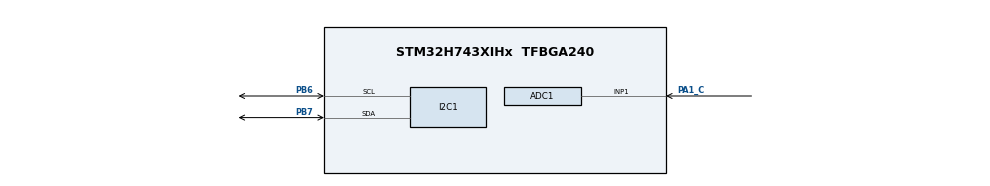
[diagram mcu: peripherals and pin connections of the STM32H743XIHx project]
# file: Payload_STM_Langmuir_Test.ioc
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ADC1.Channel-1\#ChannelRegularConversion=ADC_CHANNEL_1
ADC1.NbrOfConversionFlag=1
ADC1.OffsetNumber-1\#ChannelRegularConversion=ADC_OFFSET_NONE
ADC1.OffsetSignedSaturation-1\#ChannelRegularConversion=DISABLE
ADC1.Rank-1\#ChannelRegularConversion=1
ADC1.SamplingTime-1\#ChannelRegularConversion=ADC_SAMPLETIME_1CYCLE_5
ADC1.master=1
CORTEX_M7.default_mode_Activation=1
I2C1.Timing=0x00707CBB
Mcu.Family=STM32H7
Mcu.Name=STM32H743XIHx
Mcu.Package=TFBGA240
NVIC.PriorityGroup=NVIC_PRIORITYGROUP_4
PA1_C.Signal=ADCx_INP1
PB6.Mode=I2C
PB6.Signal=I2C1_SCL
PB7.Mode=I2C
PB7.Signal=I2C1_SDA
ProjectManager.HeapSize=0x200
ProjectManager.StackSize=0x400
ProjectManager.TargetToolchain=STM32CubeIDE
RCC.ADCFreq_Value=75000000
RCC.APB1Freq_Value=32000000
RCC.APB2Freq_Value=64000000
RCC.APB3Freq_Value=64000000
RCC.APB4Freq_Value=64000000
RCC.CortexFreq_Value=64000000
RCC.D2PPRE1=RCC_APB1_DIV2
RCC.DIVM2=4
RCC.DIVN2=9
RCC.HCLKFreq_Value=64000000
RCC.PLL2FRACN=3072
RCC.SYSCLKFreq_VALUE=64000000
RCC.USBFreq_Value=129000000
SH.ADCx_INP1.0=ADC1_INP1,IN1-Single-Ended
VP_MEMORYMAP_VS_MEMORYMAP.Mode=CurAppReg
board=custom

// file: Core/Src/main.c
/* USER CODE BEGIN Header */
/**
  ******************************************************************************
  * @file           : main.c
  * @brief          : Main program body
  ******************************************************************************
  * @attention
  *
  * Copyright (c) 2026 STMicroelectronics.
  * All rights reserved.
  *
  * This software is licensed under terms that can be found in the LICENSE file
  * in the root directory of this software component.
  * If no LICENSE file comes with this software, it is provided AS-IS.
  *
  ******************************************************************************
  */
/* USER CODE END Header */
#include "main.h"

#define MCP3021_ADDR  (0x4D << 1)  // 7-bit addr shifted for HAL
#define MEAS_BUFFER_SIZE 100 // Keep this many values

/**
 * Reads the raw 10-bit ADC value from MCP3021.
 * Returns -1 on I2C error.
 */
int32_t MCP3021_ReadRaw(I2C_HandleTypeDef *hi2c)
{
    uint8_t buf[2] = {0};

    if (HAL_I2C_Master_Receive(hi2c, MCP3021_ADDR, buf, 2, HAL_MAX_DELAY) != HAL_OK)
        return -1;

    // Data is 10-bit, MSB first, left-justified across two bytes
    // Bits [15:6] of the 16-bit word are the ADC data
    uint16_t raw = ((uint16_t)buf[0] << 8) | buf[1];
    raw = (raw >> 2) & 0x03FF;  // shift right 2, mask to 10 bits (SAR format)

    return (int32_t)raw;
}

/**
 * Converts raw ADC value to voltage (assuming 3.3V reference).
 */
float MCP3021_ReadVoltage(I2C_HandleTypeDef *hi2c)
{
    int32_t raw = MCP3021_ReadRaw(hi2c);
    if (raw < 0) return -1.0f;

    return ((float)raw / 1023.0f) * 3.3f;
}

ADC_HandleTypeDef hadc1;

I2C_HandleTypeDef hi2c1;

void SystemClock_Config(void);
static void MPU_Config(void);
static void MX_GPIO_Init(void);
static void MX_I2C1_Init(void);
static void MX_ADC1_Init(void);

int main(void)
{

  /* MPU Configuration--------------------------------------------------------*/
  MPU_Config();

  /* MCU Configuration--------------------------------------------------------*/

  /* Reset of all peripherals, Initializes the Flash interface and the Systick. */
  HAL_Init();

  /* Configure the system clock */
  SystemClock_Config();

  /* Initialize all configured peripherals */
  MX_GPIO_Init();
  MX_I2C1_Init();
  MX_ADC1_Init();
  /* USER CODE BEGIN 2 */

  HAL_ADCEx_Calibration_Start(&hadc1, ADC_CALIB_OFFSET, ADC_SINGLE_ENDED);

  /* USER CODE END 2 */

  /* Infinite loop */
  while (1)
  {

	    uint8_t buf[2] = {0};
	    i2c_status = HAL_I2C_Master_Receive(&hi2c1, MCP3021_ADDR, buf, 2, HAL_MAX_DELAY);
	    i2c_error  = HAL_I2C_GetError(&hi2c1);

	    // Read raw voltages
	    voltage_triangle = MCP3021_ReadVoltage(&hi2c1);
	    voltage_langmuir = ReadInternalADC(); // Read voltages

	    // Calculate voltage and current
	    voltage = (voltage_triangle * 169.0f) - 266.4f;
	    current = (((voltage_langmuir * 70.3f) - 109.9f) - voltage) / 3000.0f; // Calculate current and voltage

	    // Add to memory
	    measurements_voltage[meas_index] = voltage;
	    measurements_current[meas_index] = current;
	    meas_index = (meas_index + 1) % MEAS_BUFFER_SIZE;

	    HAL_Delay(100);  // Read every 100ms

  }
}

void SystemClock_Config(void)
{
  RCC_OscInitTypeDef RCC_OscInitStruct = {0};
  RCC_ClkInitTypeDef RCC_ClkInitStruct = {0};

  /** Supply configuration update enable
  */
  HAL_PWREx_ConfigSupply(PWR_LDO_SUPPLY);

  /** Configure the main internal regulator output voltage
  */
  __HAL_PWR_VOLTAGESCALING_CONFIG(PWR_REGULATOR_VOLTAGE_SCALE3);

  while(!__HAL_PWR_GET_FLAG(PWR_FLAG_VOSRDY)) {}

  /** Macro to configure the PLL clock source
  */
  __HAL_RCC_PLL_PLLSOURCE_CONFIG(RCC_PLLSOURCE_HSI);

  /** Initializes the RCC Oscillators according to the specified parameters
  * in the RCC_OscInitTypeDef structure.
  */
  RCC_OscInitStruct.OscillatorType = RCC_OSCILLATORTYPE_HSI;
  RCC_OscInitStruct.HSIState = RCC_HSI_DIV1;
  RCC_OscInitStruct.HSICalibrationValue = RCC_HSICALIBRATION_DEFAULT;
  RCC_OscInitStruct.PLL.PLLState = RCC_PLL_NONE;
  if (HAL_RCC_OscConfig(&RCC_OscInitStruct) != HAL_OK)
  {
    Error_Handler();
  }

  /** Initializes the CPU, AHB and APB buses clocks
  */
  RCC_ClkInitStruct.ClockType = RCC_CLOCKTYPE_HCLK|RCC_CLOCKTYPE_SYSCLK
                              |RCC_CLOCKTYPE_PCLK1|RCC_CLOCKTYPE_PCLK2
                              |RCC_CLOCKTYPE_D3PCLK1|RCC_CLOCKTYPE_D1PCLK1;
  RCC_ClkInitStruct.SYSCLKSource = RCC_SYSCLKSOURCE_HSI;
  RCC_ClkInitStruct.SYSCLKDivider = RCC_SYSCLK_DIV1;
  RCC_ClkInitStruct.AHBCLKDivider = RCC_HCLK_DIV1;
  RCC_ClkInitStruct.APB3CLKDivider = RCC_APB3_DIV1;
  RCC_ClkInitStruct.APB1CLKDivider = RCC_APB1_DIV2;
  RCC_ClkInitStruct.APB2CLKDivider = RCC_APB2_DIV1;
  RCC_ClkInitStruct.APB4CLKDivider = RCC_APB4_DIV1;

  if (HAL_RCC_ClockConfig(&RCC_ClkInitStruct, FLASH_LATENCY_1) != HAL_OK)
  {
    Error_Handler();
  }
}

static void MX_ADC1_Init(void)
{

  ADC_MultiModeTypeDef multimode = {0};
  ADC_ChannelConfTypeDef sConfig = {0};

  /** Common config
  */
  hadc1.Instance = ADC1;
  hadc1.Init.ClockPrescaler = ADC_CLOCK_ASYNC_DIV2;
  hadc1.Init.Resolution = ADC_RESOLUTION_16B;
  hadc1.Init.ScanConvMode = ADC_SCAN_DISABLE;
  hadc1.Init.EOCSelection = ADC_EOC_SINGLE_CONV;
  hadc1.Init.LowPowerAutoWait = DISABLE;
  hadc1.Init.ContinuousConvMode = DISABLE;
  hadc1.Init.NbrOfConversion = 1;
  hadc1.Init.DiscontinuousConvMode = DISABLE;
  hadc1.Init.ExternalTrigConv = ADC_SOFTWARE_START;
  hadc1.Init.ExternalTrigConvEdge = ADC_EXTERNALTRIGCONVEDGE_NONE;
  hadc1.Init.ConversionDataManagement = ADC_CONVERSIONDATA_DR;
  hadc1.Init.Overrun = ADC_OVR_DATA_PRESERVED;
  hadc1.Init.LeftBitShift = ADC_LEFTBITSHIFT_NONE;
  hadc1.Init.OversamplingMode = DISABLE;
  hadc1.Init.Oversampling.Ratio = 1;
  if (HAL_ADC_Init(&hadc1) != HAL_OK)
  {
    Error_Handler();
  }

  /** Configure the ADC multi-mode
  */
  multimode.Mode = ADC_MODE_INDEPENDENT;
  if (HAL_ADCEx_MultiModeConfigChannel(&hadc1, &multimode) != HAL_OK)
  {
    Error_Handler();
  }

  /** Configure Regular Channel
  */
  sConfig.Channel = ADC_CHANNEL_1;
  sConfig.Rank = ADC_REGULAR_RANK_1;
  sConfig.SamplingTime = ADC_SAMPLETIME_1CYCLE_5;
  sConfig.SingleDiff = ADC_SINGLE_ENDED;
  sConfig.OffsetNumber = ADC_OFFSET_NONE;
  sConfig.Offset = 0;
  sConfig.OffsetSignedSaturation = DISABLE;
  if (HAL_ADC_ConfigChannel(&hadc1, &sConfig) != HAL_OK)
  {
    Error_Handler();
  }

}

static void MX_I2C1_Init(void)
{

  hi2c1.Instance = I2C1;
  hi2c1.Init.Timing = 0x00707CBB;
  hi2c1.Init.OwnAddress1 = 0;
  hi2c1.Init.AddressingMode = I2C_ADDRESSINGMODE_7BIT;
  hi2c1.Init.DualAddressMode = I2C_DUALADDRESS_DISABLE;
  hi2c1.Init.OwnAddress2 = 0;
  hi2c1.Init.OwnAddress2Masks = I2C_OA2_NOMASK;
  hi2c1.Init.GeneralCallMode = I2C_GENERALCALL_DISABLE;
  hi2c1.Init.NoStretchMode = I2C_NOSTRETCH_DISABLE;
  if (HAL_I2C_Init(&hi2c1) != HAL_OK)
  {
    Error_Handler();
  }

  /** Configure Analogue filter
  */
  if (HAL_I2CEx_ConfigAnalogFilter(&hi2c1, I2C_ANALOGFILTER_ENABLE) != HAL_OK)
  {
    Error_Handler();
  }

  /** Configure Digital filter
  */
  if (HAL_I2CEx_ConfigDigitalFilter(&hi2c1, 0) != HAL_OK)
  {
    Error_Handler();
  }

}

static void MX_GPIO_Init(void)
{

  /* GPIO Ports Clock Enable */
  __HAL_RCC_GPIOB_CLK_ENABLE();
  __HAL_RCC_GPIOA_CLK_ENABLE();

}

 /* MPU Configuration */

void MPU_Config(void)
{
  MPU_Region_InitTypeDef MPU_InitStruct = {0};

  /* Disables the MPU */
  HAL_MPU_Disable();

  /** Initializes and configures the Region and the memory to be protected
  */
  MPU_InitStruct.Enable = MPU_REGION_ENABLE;
  MPU_InitStruct.Number = MPU_REGION_NUMBER0;
  MPU_InitStruct.BaseAddress = 0x0;
  MPU_InitStruct.Size = MPU_REGION_SIZE_4GB;
  MPU_InitStruct.SubRegionDisable = 0x87;
  MPU_InitStruct.TypeExtField = MPU_TEX_LEVEL0;
  MPU_InitStruct.AccessPermission = MPU_REGION_NO_ACCESS;
  MPU_InitStruct.DisableExec = MPU_INSTRUCTION_ACCESS_DISABLE;
  MPU_InitStruct.IsShareable = MPU_ACCESS_SHAREABLE;
  MPU_InitStruct.IsCacheable = MPU_ACCESS_NOT_CACHEABLE;
  MPU_InitStruct.IsBufferable = MPU_ACCESS_NOT_BUFFERABLE;

  HAL_MPU_ConfigRegion(&MPU_InitStruct);
  /* Enables the MPU */
  HAL_MPU_Enable(MPU_PRIVILEGED_DEFAULT);

}

void Error_Handler(void)
{
  __disable_irq();
  while (1)
  {
  }
}
